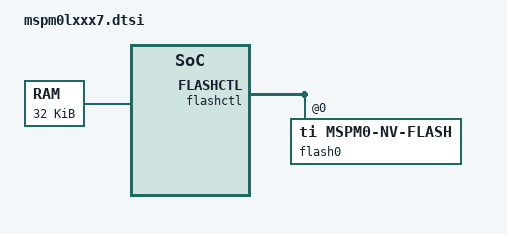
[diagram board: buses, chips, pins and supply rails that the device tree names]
/* SPDX-License-Identifier: Apache-2.0 */

#include <mem.h>
#include <ti/mspm0l122x_l222x/mspm0l122x_l222x.dtsi>

/ {
	sram0: memory@20200000 {
		reg = <0x20200000 DT_SIZE_K(32)>;
	};
};

&flashctl {
	flash0: nv-flash@0 {
		compatible = "ti,mspm0-nv-flash", "soc-nv-flash";
		erase-block-size = <1024>;
		write-block-size = <8>;
		reg = <0x0 DT_SIZE_K(128)>;
	};
};
